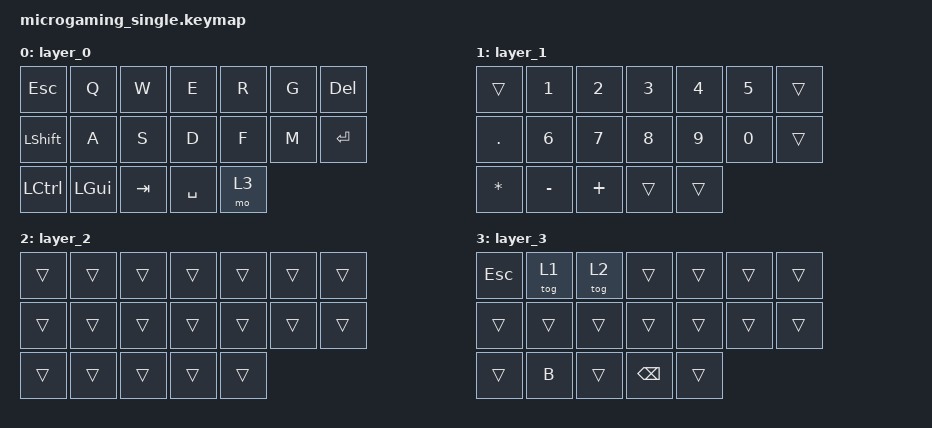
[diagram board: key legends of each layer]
#include <behaviors.dtsi>
#include <dt-bindings/zmk/keys.h>

 / {
     keymap {
         compatible = "zmk,keymap";

         layer_0 {
             bindings = <
                        &kp ESC &kp Q &kp W &kp E &kp R &kp G &kp DEL
                        &kp LSHFT &kp A &kp S &kp D &kp F &kp M &kp ENTER
                        &kp LCTRL &kp LGUI &kp TAB &kp SPACE &mo 3
                    >;
         };

         layer_1 {
             bindings = <
                        &trans &kp N1 &kp N2 &kp N3 &kp N4 &kp N5 &trans
                        &kp DOT &kp N6 &kp N7 &kp N8 &kp N9 &kp N0 &trans
                        &kp ASTERISK &kp MINUS &kp PLUS &trans &trans
                    >;
         };

         layer_2 {
             bindings = <
                        &trans &trans &trans 2 &trans 3 &trans &trans &trans
                        &trans &trans &trans &trans &trans &trans &trans
                        &trans &trans &trans &trans &trans
                    >;
         };

         layer_3 {
             bindings = <
                        &kp ESC &tog 1 &tog 2 &trans &trans &trans &trans
                        &trans &trans &trans &trans &trans &trans &trans
                        &trans &kp B &trans &kp BSPC &trans
                    >;
         };
     };
 };
